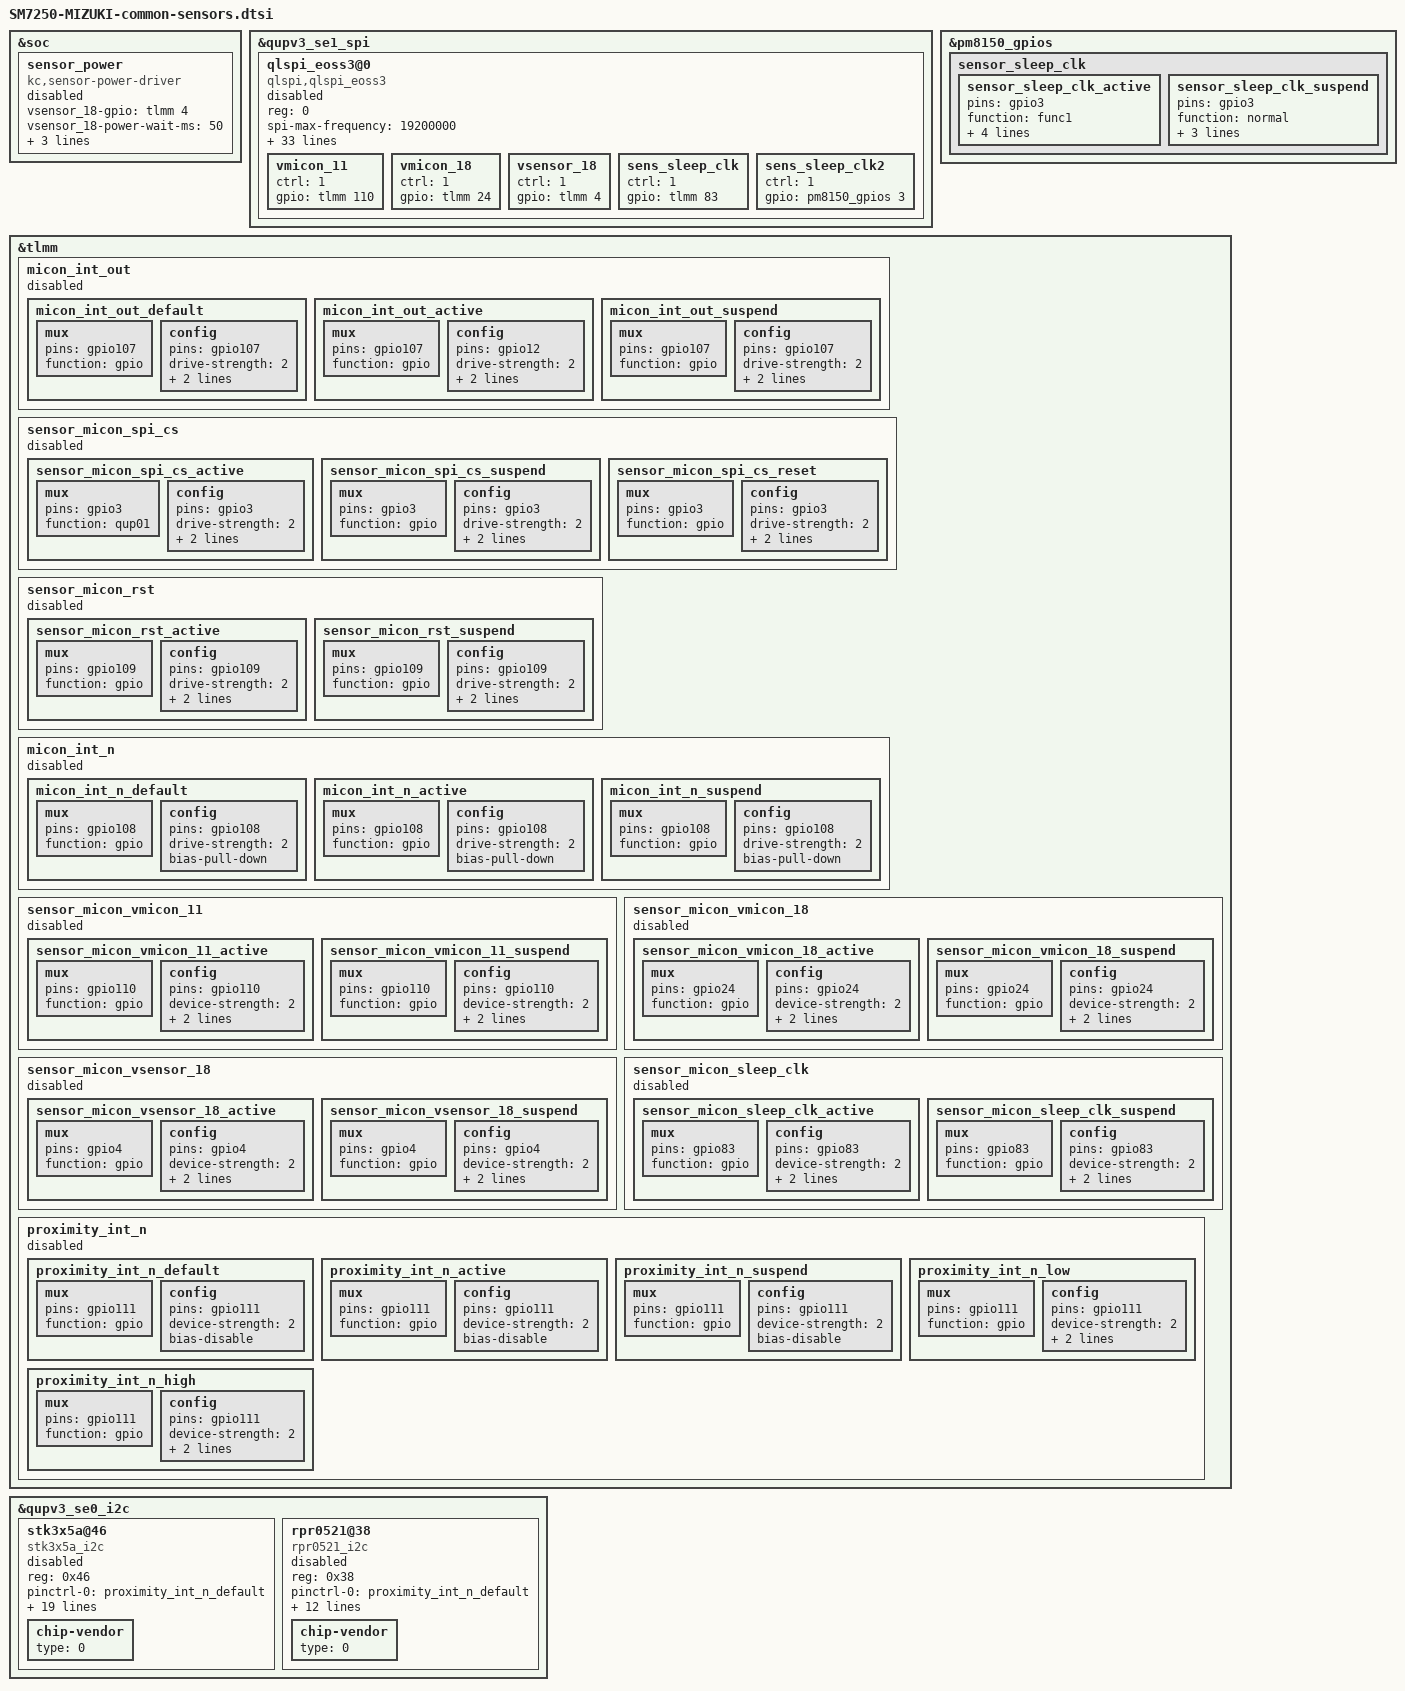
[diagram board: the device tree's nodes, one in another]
/*
 * This software is contributed or developed by KYOCERA Corporation.
 * (C) 2020 KYOCERA Corporation
 *
 * This program is free software; you can redistribute it and/or modify
 * it under the terms of the GNU General Public License version 2 and
 * only version 2 as published by the Free Software Foundation.
 *
 * This program is distributed in the hope that it will be useful,
 * but WITHOUT ANY WARRANTY; without even the implied warranty of
 * MERCHANTABILITY or FITNESS FOR A PARTICULAR PURPOSE.  See the
 * GNU General Public License for more details.
 */

&soc {
	sensor_power {
		status = "disabled";
		compatible = "kc,sensor-power-driver";
//		sens_sleep_clk-gpio = <&pm8909_gpios 2 0>;
//		vsensor-gpio-ctrl;
//		vsensor_18-supply = <&pm8909_l**>;
		vsensor_18-gpio = <&tlmm 4 0>;
		vsensor_18-power-wait-ms = <50>;
		vsensor_18-voltage-min = <1800000>;
		vsensor_18-voltage-max = <1800000>;
		vsensor_18-load = <50000>;
	};
};
&qupv3_se1_spi {
	qlspi_eoss3@0 {
		status = "disabled";
		compatible = "qlspi,qlspi_eoss3";
		reg = <0>;
		spi-max-frequency = <19200000>;
		spi-min-frequency = <640000>;
		pinctrl-names = "sensor_micon_default", "sensor_micon_active", "sensor_micon_sleep",
				"sensor_micon_spi_cs_active", "sensor_micon_spi_cs_suspend", "sensor_micon_spi_cs_reset",
				"sensor_micon_rst_active", "sensor_micon_rst_suspend",
				"sensor_micon_vmicon_11_active","sensor_micon_vmicon_11_suspend",
				"sensor_micon_vmicon_18_active","sensor_micon_vmicon_18_suspend",
				"sensor_micon_sleep_clk_active","sensor_micon_sleep_clk_suspend",
				"sensor_micon_vsensor_18_active","sensor_micon_vsensor_18_suspend",
				"sensor_sleep_clk_active","sensor_sleep_clk_suspend",
				"spi_default", "spi_sleep", "sensor_micon_spi_cs_request";
		pinctrl-0 = <&micon_int_n_default &micon_int_out_default>;
		pinctrl-1 = <&micon_int_n_active &micon_int_out_active>;
		pinctrl-2 = <&micon_int_n_suspend &micon_int_out_suspend>;
		pinctrl-3 = <&sensor_micon_spi_cs_active>;
		pinctrl-4 = <&sensor_micon_spi_cs_suspend>;
		pinctrl-5 = <&sensor_micon_spi_cs_reset>;
		pinctrl-6 = <&sensor_micon_rst_active>;
		pinctrl-7 = <&sensor_micon_rst_suspend>;
		pinctrl-8 = <&sensor_micon_vmicon_11_active>;
		pinctrl-9 = <&sensor_micon_vmicon_11_suspend>;
		pinctrl-10 = <&sensor_micon_vmicon_18_active>;
		pinctrl-11 = <&sensor_micon_vmicon_18_suspend>;
		pinctrl-12 = <&sensor_micon_sleep_clk_active>;
		pinctrl-13 = <&sensor_micon_sleep_clk_suspend>;
		pinctrl-14 = <&sensor_micon_vsensor_18_active>;
		pinctrl-15 = <&sensor_micon_vsensor_18_suspend>;
		pinctrl-16 = <&sensor_sleep_clk_active>;
		pinctrl-17 = <&sensor_sleep_clk_suspend>;
/*
		pinctrl-18 = <&spi_micon_mosi_active
				 	  &spi_micon_miso_active
				 	  &spi_micon_clk_active>;
		pinctrl-19 = <&spi_micon_mosi_suspend
				 	  &spi_micon_miso_suspend
				 	  &spi_micon_clk_suspend>;
		pinctrl-20 = <&sensor_micon_spi_cs_request>;
*/
		qlspi,rst-gpio = <&tlmm 109 0>;
		qlspi,irq-out-gpio = <&tlmm 107 0>;
		qlspi,irq-gpio = <&tlmm 108 0>;
		qlspi,cs-gpio = <&tlmm 3 0>;
		qlspi,fabrdy-gpio = <&tlmm 7 0>;

		spi-cs-low; /* CS Active Level LOW */
		micon-acc-conv_axis = /bits/ 8 <0>;
		micon-gyro-conv_axis = /bits/ 8 <0>;
		micon-mag-conv_axis = /bits/ 8 <0>;
		micon-mag-static_matrix = <0x2710 0x0 0x0 0x0 0x2710 0x0 0x0 0x0 0x2710>; /* 10000, 0, 0, 0, 10000, 0, 0, 0, 10000 */

		vmicon_11 {
			ctrl = <1>; /* 1:pinctrl, 2:pm ldo, 3:pm gpio*/
			gpio = <&tlmm 110 0>;
		};
		vmicon_18 {
			ctrl = <1>; /* 1:pinctrl, 2:pm ldo, 3:pm gpio*/
			gpio = <&tlmm 24 0>;
		};
		vsensor_18 {
			ctrl = <1>; /* 1:pinctrl, 2:pm ldo, 3:pm gpio*/
			gpio = <&tlmm 4 0>;
		};
		sens_sleep_clk {
			ctrl = <1>; /* 1:pinctrl, 2:pm ldo, 3:pm gpio*/
			gpio = <&tlmm 83 0>;
		};
		sens_sleep_clk2 {
			ctrl = <1>; /* 1:pinctrl, 2:pm ldo, 3:pm gpio*/
			gpio = <&pm8150_gpios 3 0>;
		};
	};
};

&pm8150_gpios {
	sensor_sleep_clk {
		status = "ok";
		sensor_sleep_clk_active: sensor_sleep_clk_active {
			pins = "gpio3";
 			function = "func1";
 			bias-disable;
 			power-source = <0>;
 			output-enable;
 			qcom,drive-strength = <1>;
		};
		sensor_sleep_clk_suspend: sensor_sleep_clk_suspend {
			pins = "gpio3";
			function = "normal";
			bias-pull-down;
			input-enable;
			power-source = <0>;
		};
	};
};

&tlmm {
	micon_int_out {
		status = "disabled";
		micon_int_out_default: micon_int_out_default {
			mux {
				pins = "gpio107";
				function = "gpio";
			};
			config {
				pins = "gpio107";
				drive-strength = <2>;
				bias-disable;
				ouput-low;
			};
		};
		micon_int_out_active: micon_int_out_active {
			mux {
				pins = "gpio107";
				function = "gpio";
			};
			config {
				pins = "gpio12";
				drive-strength = <2>;
				bias-disable;
				ouput-low;
			};
		};
		micon_int_out_suspend: micon_int_out_suspend {
			mux {
				pins = "gpio107";
				function = "gpio";
			};
			config {
				pins = "gpio107";
				drive-strength = <2>;
				bias-disable;
				ouput-low;
			};
		};
	};

	sensor_micon_spi_cs {
		status = "disabled";
		sensor_micon_spi_cs_active: sensor_micon_spi_cs_active {
			mux {
				pins = "gpio3";
				function = "qup01";
			};
			config {
				pins = "gpio3";
				drive-strength = <2>;
				bias-disable;
				output-high;
			};
		};
		sensor_micon_spi_cs_suspend: sensor_micon_spi_cs_suspend {
			mux {
				pins = "gpio3";
				function = "gpio";
			};
			config {
				pins = "gpio3";
				drive-strength = <2>;
				bias-disable;
				output-low;
			};
		};
		sensor_micon_spi_cs_reset: sensor_micon_spi_cs_reset {
			mux {
				pins = "gpio3";
				function = "gpio";
			};
			config {
				pins = "gpio3";
				drive-strength = <2>;
				bias-disable;
				output-high;
			};
		};
	};
	sensor_micon_rst {
		status = "disabled";
		sensor_micon_rst_active: sensor_micon_rst_active {
			mux {
				pins = "gpio109";
				function = "gpio";
			};
			config {
				pins = "gpio109";
				drive-strength = <2>;
				bias-disable;
				output-high;
			};
		};
		sensor_micon_rst_suspend: sensor_micon_rst_suspend {
			mux {
				pins = "gpio109";
				function = "gpio";
			};
			config {
				pins = "gpio109";
				drive-strength = <2>;
				bias-disable;
				output-low;
			};
		};
	};
	micon_int_n {
		status = "disabled";
		micon_int_n_default: micon_int_n_default {
			mux {
				pins = "gpio108";
				function = "gpio";
			};
			config {
				pins = "gpio108";
				drive-strength = <2>;
				bias-pull-down;
			};
		};
		micon_int_n_active: micon_int_n_active {
			mux {
				pins = "gpio108";
				function = "gpio";
			};
			config {
				pins = "gpio108";
				drive-strength = <2>;
				bias-pull-down;
			};
		};
		micon_int_n_suspend: micon_int_n_suspend {
			mux {
				pins = "gpio108";
				function = "gpio";
			};
			config {
				pins = "gpio108";
				drive-strength = <2>;
				bias-pull-down;
			};
		};
	};
	sensor_micon_vmicon_11 {
		status = "disabled";
		sensor_micon_vmicon_11_active: sensor_micon_vmicon_11_active {
			mux {
				pins = "gpio110";
				function = "gpio";
			};
			config {
				pins = "gpio110";
				device-strength = <2>;
				output-high;
				bias-disable;
			};
		};
		sensor_micon_vmicon_11_suspend: sensor_micon_vmicon_11_suspend {
			mux {
				pins = "gpio110";
				function = "gpio";
			};
			config {
				pins = "gpio110";
				device-strength = <2>;
				output-low;
				bias-disable;
			};
		};
	};
	sensor_micon_vmicon_18 {
		status = "disabled";
		sensor_micon_vmicon_18_active: sensor_micon_vmicon_18_active {
			mux {
				pins = "gpio24";
				function = "gpio";
			};
			config {
				pins = "gpio24";
				device-strength = <2>;
				output-high;
				bias-disable;
			};
		};
		sensor_micon_vmicon_18_suspend: sensor_micon_vmicon_18_suspend {
			mux {
				pins = "gpio24";
				function = "gpio";
			};
			config {
				pins = "gpio24";
				device-strength = <2>;
				output-low;
				bias-disable;
			};
		};
	};
	sensor_micon_vsensor_18 {
		status = "disabled";
		sensor_micon_vsensor_18_active: sensor_micon_vsensor_18_active {
			mux {
				pins = "gpio4";
				function = "gpio";
			};
			config {
				pins = "gpio4";
				device-strength = <2>;
				output-high;
				bias-disable;
			};
		};
		sensor_micon_vsensor_18_suspend: sensor_micon_vsensor_18_suspend {
			mux {
				pins = "gpio4";
				function = "gpio";
			};
			config {
				pins = "gpio4";
				device-strength = <2>;
				output-low;
				bias-disable;
			};
		};
	};
	sensor_micon_sleep_clk {
		status = "disabled";
		sensor_micon_sleep_clk_active: sensor_micon_sleep_clk_active {
			mux {
				pins = "gpio83";
				function = "gpio";
			};
			config {
				pins = "gpio83";
				device-strength = <2>;
				output-high;
				bias-disable;
			};
		};
		sensor_micon_sleep_clk_suspend: sensor_micon_sleep_clk_suspend {
			mux {
				pins = "gpio83";
				function = "gpio";
			};
			config {
				pins = "gpio83";
				device-strength = <2>;
				output-low;
				bias-disable;
			};
		};
	};
	proximity_int_n {
		status = "disabled";
		proximity_int_n_default: proximity_int_n_default {
			mux {
				pins = "gpio111";
				function = "gpio";
			};
			config {
				pins = "gpio111";
				device-strength = <2>;
				bias-disable;
			};
		};
		proximity_int_n_active: proximity_int_n_active {
			mux {
				pins = "gpio111";
				function = "gpio";
			};
			config {
				pins = "gpio111";
				device-strength = <2>;
				bias-disable;
			};
		};
		proximity_int_n_suspend: proximity_int_n_suspend {
			mux {
				pins = "gpio111";
				function = "gpio";
			};
			config {
				pins = "gpio111";
				device-strength = <2>;
				bias-disable;
			};
		};
		proximity_int_n_low: proximity_int_n_low {
			mux {
				pins = "gpio111";
				function = "gpio";
			};
			config {
				pins = "gpio111";
				device-strength = <2>;
				output-low;
				bias-disable;
			};
		};
		proximity_int_n_high: proximity_int_n_high {
			mux {
				pins = "gpio111";
				function = "gpio";
			};
			config {
				pins = "gpio111";
				device-strength = <2>;
				output-low;
				bias-disable;
			};
		};
	};
//	proximity_vprox_18 {
//		status = "disabled";
//		proximity_vprox_18_active: proximity_vprox_18_active {
//			pins_cmd_dat {
//				pinmux = <PINMUX_GPIO90__FUNC_GPIO90>;
//				bias-disable;
//				output-high;
//			};
//		};
//		proximity_vprox_18_suspend: proximity_vprox_18_suspend {
//			pins_cmd_dat {
//				pinmux = <PINMUX_GPIO90__FUNC_GPIO90>;
//				bias-disable;
//				output-low;
//			};
//		};
//	};
	/*spi setting*/
//	spi_micon_mosi {
//		status = "disabled";
//		spi_micon_mosi_default: spi_micon_mosi_default {
//			pins_cmd_dat {
//				pinmux = <PINMUX_GPIO15__FUNC_GPIO15>;
//				bias-disable;
//				output-low;
//			};
//		};
//		spi_micon_mosi_active: spi_micon_mosi_active {
//			pins_cmd_dat {
//				pinmux = <PINMUX_GPIO15__FUNC_SPI4_MO>;
//				output-low;
//				bias-disable;
//			};
//		};
//		spi_micon_mosi_suspend: spi_micon_mosi_suspend {
//			pins_cmd_dat {
//				pinmux = <PINMUX_GPIO15__FUNC_GPIO15>;
//				bias-disable;
//				output-low;
//			};
//		};
//	};
//	spi_micon_miso {
//		status = "disabled";
//		spi_micon_miso_default: spi_micon_miso_default {
//			pins_cmd_dat {
//				pinmux = <PINMUX_GPIO13__FUNC_GPIO13>;
//				slew-rate = <0>;
//				bias-pull-down;
//			};
//		};
//		spi_micon_miso_active: spi_micon_miso_active {
//			pins_cmd_dat {
//				pinmux = <PINMUX_GPIO13__FUNC_SPI4_MI>;
//				slew-rate = <0>;
//				input-enable;
//				bias-pull-down;
//			};
//		};
//		spi_micon_miso_suspend: spi_micon_miso_suspend {
//			pins_cmd_dat {
//				pinmux = <PINMUX_GPIO13__FUNC_GPIO13>;
//				slew-rate = <0>;
//				bias-pull-down;
//			};
//		};
//	};
//	spi_micon_clk {
//		status = "disabled";
//		spi_micon_clk_default: spi_micon_clk_default {
//			pins_cmd_dat {
//				pinmux = <PINMUX_GPIO16__FUNC_GPIO16>;
//				bias-disable;
//				output-low;
//			};
//		};
//		spi_micon_clk_active: spi_micon_clk_active {
//			pins_cmd_dat {
//				pinmux = <PINMUX_GPIO16__FUNC_SPI4_CLK>;
//				bias-disable;
//				output-low;
//			};
//		};
//		spi_micon_clk_suspend: spi_micon_clk_suspend {
//			pins_cmd_dat {
//				pinmux = <PINMUX_GPIO16__FUNC_GPIO16>;
//				bias-disable;
//				output-low;
//			};
//		};
//	};
};

&qupv3_se0_i2c {
	stk3x5a@46 { /* Ambient light and proximity sensor */
		status = "disabled";
		compatible = "stk3x5a_i2c";
		reg = <0x46>;

		pinctrl-names = "default","active","suspend";
/*						"proxmity_vprox_32_active", "proxmity_vprox_32_suspend",
						"proxmity_vprox_18_active", "proxmity_vprox_18_suspend";*/
		pinctrl-0 = <&proximity_int_n_default>;
		pinctrl-1 = <&proximity_int_n_active>;
		pinctrl-2 = <&proximity_int_n_suspend>;
//		pinctrl-3 = <&proximity_vprox_32_active>;
//		pinctrl-4 = <&proximity_vprox_32_suspend>;
//		pinctrl-5 = <&proximity_vprox_18_active>;
//		pinctrl-6 = <&proximity_vprox_18_suspend>;
		interrupt-parent = <&tlmm>;
		interrupts = <111 0x2002>;
		stk3338,irq-gpio = <&tlmm 111 0>;
		stk3338,psals-power-offon-interval-ms = <10>;
		stk3338,psals-power-on-wait-ms = <5>;
		stk3338,psals-power-normal-wait-ms = <1>;
		stk3338,psals-PMIC-supply-ctrl;
//		stk3338,psals-vleda-is-gpio; /*If you control vleda via vreg, you should delete this property */
//		stk3338,psals-vdd-is-gpio; /*If you control vleda via vreg, you should delete this property */
		/* regulator VLEDA(3.2V)*/
		psals-vleda-supply = <&pm8150_l10>;
		psals-vleda-min-voltage = <3200000>;
		psals-vleda-max-voltage = <3200000>;
		psals-vleda-on-load-current  = <100000>;
		psals-vleda-off-load-current = <1000>;
		/* regulator VLEDA(1.8V)*/
		psals-vdd-supply = <&pm8150a_l1>;
		psals-vdd-min-voltage = <1800000>;
		psals-vdd-max-voltage = <1800000>;
		psals-vdd-on-load-current  = <100000>;
		psals-vdd-off-load-current = <1000>;
		chip-vendor {
			type = <0>; /* 0:Qcom, 1:MediaTek */
		};
	};

	rpr0521@38 { /* Ambient light and proximity sensor */
		status = "disabled";
		compatible = "rpr0521_i2c";
		reg = <0x38>;
		pinctrl-names = "default","active","suspend";
		pinctrl-0 = <&proximity_int_n_default>;
		pinctrl-1 = <&proximity_int_n_active>;
		pinctrl-2 = <&proximity_int_n_suspend>;
		interrupt-parent = <&tlmm>;
		interrupts = <6 0x2002>;
		rpr0521,irq-gpio = <&tlmm 6 0>;
		rpr0521,psals-power-offon-interval-ms = <10>;
		rpr0521,psals-power-on-wait-ms = <5>;
		rpr0521,psals-power-normal-wait-ms = <1>;
		//stk3338,psals-PMIC-supply-ctrl;
		//psals-vcc-supply = <&mt_pmic_vio28_ldo_reg>;
		psals-vcc-min-voltage = <3300000>;
		psals-vcc-max-voltage = <3300000>;
		psals-vcc-on-load-current = <5000>;
		psals-vcc-off-load-current = <300>;
		chip-vendor {
			type = <0>; /* 0:Qcom, 1:MediaTek */
		};
	};
};
